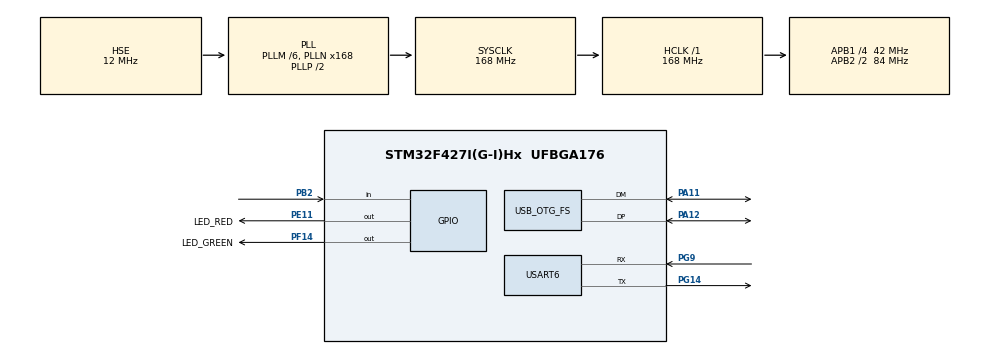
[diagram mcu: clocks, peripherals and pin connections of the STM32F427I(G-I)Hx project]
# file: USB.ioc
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Dma.Request0=USART6_RX
Dma.Request1=USART6_TX
Dma.USART6_RX.0.Direction=DMA_PERIPH_TO_MEMORY
Dma.USART6_RX.0.FIFOMode=DMA_FIFOMODE_DISABLE
Dma.USART6_RX.0.Instance=DMA2_Stream1
Dma.USART6_RX.0.MemDataAlignment=DMA_MDATAALIGN_BYTE
Dma.USART6_RX.0.MemInc=DMA_MINC_ENABLE
Dma.USART6_RX.0.Mode=DMA_NORMAL
Dma.USART6_RX.0.PeriphDataAlignment=DMA_PDATAALIGN_BYTE
Dma.USART6_RX.0.PeriphInc=DMA_PINC_DISABLE
Dma.USART6_RX.0.Priority=DMA_PRIORITY_LOW
Dma.USART6_TX.1.Direction=DMA_MEMORY_TO_PERIPH
Dma.USART6_TX.1.FIFOMode=DMA_FIFOMODE_DISABLE
Dma.USART6_TX.1.Instance=DMA2_Stream6
Dma.USART6_TX.1.MemDataAlignment=DMA_MDATAALIGN_BYTE
Dma.USART6_TX.1.MemInc=DMA_MINC_ENABLE
Dma.USART6_TX.1.Mode=DMA_NORMAL
Dma.USART6_TX.1.PeriphDataAlignment=DMA_PDATAALIGN_BYTE
Dma.USART6_TX.1.PeriphInc=DMA_PINC_DISABLE
Dma.USART6_TX.1.Priority=DMA_PRIORITY_LOW
Mcu.Family=STM32F4
Mcu.Name=STM32F427I(G-I)Hx
Mcu.Package=UFBGA176
NVIC.DMA2_Stream1_IRQn=true\:0\:0\:false\:false\:true\:false\:true\:true
NVIC.DMA2_Stream6_IRQn=true\:0\:0\:false\:false\:true\:false\:true\:true
NVIC.OTG_FS_IRQn=true\:0\:0\:false\:false\:true\:false\:true\:true
NVIC.PriorityGroup=NVIC_PRIORITYGROUP_4
NVIC.USART6_IRQn=true\:0\:0\:false\:false\:true\:true\:true\:true
PA11.Mode=Device_Only
PA11.Signal=USB_OTG_FS_DM
PA12.Mode=Device_Only
PA12.Signal=USB_OTG_FS_DP
PB2/BOOT1.Signal=GPIO_Input
PE11.GPIO_Label=LED_RED
PE11.Signal=GPIO_Output
PF14.GPIO_Label=LED_GREEN
PF14.Signal=GPIO_Output
PG14.Mode=Asynchronous
PG14.Signal=USART6_TX
PG9.Mode=Asynchronous
PG9.Signal=USART6_RX
PH0/OSC_IN.Mode=HSE-External-Oscillator
PH0/OSC_IN.Signal=RCC_OSC_IN
PH1/OSC_OUT.Mode=HSE-External-Oscillator
PH1/OSC_OUT.Signal=RCC_OSC_OUT
ProjectManager.HeapSize=0x1000
ProjectManager.StackSize=0x400
ProjectManager.TargetToolchain=Makefile
RCC.48MHZClocksFreq_Value=48000000
RCC.AHBFreq_Value=168000000
RCC.APB1CLKDivider=RCC_HCLK_DIV4
RCC.APB1Freq_Value=42000000
RCC.APB1TimFreq_Value=84000000
RCC.APB2CLKDivider=RCC_HCLK_DIV2
RCC.APB2Freq_Value=84000000
RCC.APB2TimFreq_Value=168000000
RCC.CortexFreq_Value=168000000
RCC.HCLKFreq_Value=168000000
RCC.HSE_VALUE=12000000
RCC.HSI_VALUE=16000000
RCC.LSE_VALUE=32768
RCC.PLLM=6
RCC.PLLN=168
RCC.PLLQ=7
RCC.SYSCLKFreq_VALUE=168000000
RCC.SYSCLKSource=RCC_SYSCLKSOURCE_PLLCLK
RCC.VCOOutputFreq_Value=336000000
USART6.VirtualMode=VM_ASYNC
USB_DEVICE.CLASS_NAME_FS=CDC
USB_DEVICE.VirtualMode-CDC_FS=Cdc
USB_DEVICE.VirtualModeFS=Cdc_FS
USB_OTG_FS.VirtualMode=Device_Only
VP_USB_DEVICE_VS_USB_DEVICE_CDC_FS.Mode=CDC_FS
board=USB

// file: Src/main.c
/**
  ******************************************************************************
  * @file           : main.c
  * @brief          : Main program body
  ******************************************************************************
  * This notice applies to any and all portions of this file
  * that are not between comment pairs USER CODE BEGIN and
  * USER CODE END. Other portions of this file, whether
  * inserted by the user or by software development tools
  * are owned by their respective copyright owners.
  *
  * Copyright (c) 2022 STMicroelectronics International N.V.
  * All rights reserved.
  *
  * Redistribution and use in source and binary forms, with or without
  * modification, are permitted, provided that the following conditions are met:
  *
  * 1. Redistribution of source code must retain the above copyright notice,
  *    this list of conditions and the following disclaimer.
  * 2. Redistributions in binary form must reproduce the above copyright notice,
  *    this list of conditions and the following disclaimer in the documentation
  *    and/or other materials provided with the distribution.
  * 3. Neither the name of STMicroelectronics nor the names of other
  *    contributors to this software may be used to endorse or promote products
  *    derived from this software without specific written permission.
  * 4. This software, including modifications and/or derivative works of this
  *    software, must execute solely and exclusively on microcontroller or
  *    microprocessor devices manufactured by or for STMicroelectronics.
  * 5. Redistribution and use of this software other than as permitted under
  *    this license is void and will automatically terminate your rights under
  *    this license.
  *
  * THIS SOFTWARE IS PROVIDED BY STMICROELECTRONICS AND CONTRIBUTORS "AS IS"
  * AND ANY EXPRESS, IMPLIED OR STATUTORY WARRANTIES, INCLUDING, BUT NOT
  * LIMITED TO, THE IMPLIED WARRANTIES OF MERCHANTABILITY, FITNESS FOR A
  * PARTICULAR PURPOSE AND NON-INFRINGEMENT OF THIRD PARTY INTELLECTUAL PROPERTY
  * RIGHTS ARE DISCLAIMED TO THE FULLEST EXTENT PERMITTED BY LAW. IN NO EVENT
  * SHALL STMICROELECTRONICS OR CONTRIBUTORS BE LIABLE FOR ANY DIRECT, INDIRECT,
  * INCIDENTAL, SPECIAL, EXEMPLARY, OR CONSEQUENTIAL DAMAGES (INCLUDING, BUT NOT
  * LIMITED TO, PROCUREMENT OF SUBSTITUTE GOODS OR SERVICES; LOSS OF USE, DATA,
  * OR PROFITS; OR BUSINESS INTERRUPTION) HOWEVER CAUSED AND ON ANY THEORY OF
  * LIABILITY, WHETHER IN CONTRACT, STRICT LIABILITY, OR TORT (INCLUDING
  * NEGLIGENCE OR OTHERWISE) ARISING IN ANY WAY OUT OF THE USE OF THIS SOFTWARE,
  * EVEN IF ADVISED OF THE POSSIBILITY OF SUCH DAMAGE.
  *
  ******************************************************************************
  */
#include "main.h"
#include "stm32f4xx_hal.h"
#include "dma.h"
#include "usart.h"
#include "usb_device.h"
#include "gpio.h"

/* USER CODE BEGIN PV */
/* Private variables ---------------------------------------------------------*/

uint8_t KeyStatus;
extern uint8_t UART_RxBuffer[2048];
/* USER CODE END PV */

void SystemClock_Config(void);

/* USER CODE BEGIN PFP */
/* Private function prototypes -----------------------------------------------*/

/* USER CODE END PFP */

int main(void)
{

  /* MCU Configuration----------------------------------------------------------*/

  /* Reset of all peripherals, Initializes the Flash interface and the Systick. */
  HAL_Init();

  /* Configure the system clock */
  SystemClock_Config();

  /* Initialize all configured peripherals */
  MX_GPIO_Init();
  MX_DMA_Init();
  MX_USB_DEVICE_Init();
  MX_USART6_UART_Init();
  /* USER CODE BEGIN 2 */
	led_off();
  /* Start UART Receive With IDLE Interrupt */
  HAL_UART_Receive_IT_IDLE(&huart6,UART_RxBuffer,2048);

  /* USER CODE END 2 */

  /* Infinite loop */
  while (1)
  {

  /* USER CODE BEGIN 3 */
	HAL_GPIO_TogglePin(LED_GREEN_GPIO_Port, LED_GREEN_Pin);
	HAL_Delay(500);
  }
  /* USER CODE END 3 */

}

void SystemClock_Config(void)
{

  RCC_OscInitTypeDef RCC_OscInitStruct;
  RCC_ClkInitTypeDef RCC_ClkInitStruct;

    /**Configure the main internal regulator output voltage
    */
  __HAL_RCC_PWR_CLK_ENABLE();

  __HAL_PWR_VOLTAGESCALING_CONFIG(PWR_REGULATOR_VOLTAGE_SCALE1);

    /**Initializes the CPU, AHB and APB busses clocks
    */
  RCC_OscInitStruct.OscillatorType = RCC_OSCILLATORTYPE_HSE;
  RCC_OscInitStruct.HSEState = RCC_HSE_ON;
  RCC_OscInitStruct.PLL.PLLState = RCC_PLL_ON;
  RCC_OscInitStruct.PLL.PLLSource = RCC_PLLSOURCE_HSE;
  RCC_OscInitStruct.PLL.PLLM = 6;
  RCC_OscInitStruct.PLL.PLLN = 168;
  RCC_OscInitStruct.PLL.PLLP = RCC_PLLP_DIV2;
  RCC_OscInitStruct.PLL.PLLQ = 7;
  if (HAL_RCC_OscConfig(&RCC_OscInitStruct) != HAL_OK)
  {
    _Error_Handler(__FILE__, __LINE__);
  }

    /**Initializes the CPU, AHB and APB busses clocks
    */
  RCC_ClkInitStruct.ClockType = RCC_CLOCKTYPE_HCLK|RCC_CLOCKTYPE_SYSCLK
                              |RCC_CLOCKTYPE_PCLK1|RCC_CLOCKTYPE_PCLK2;
  RCC_ClkInitStruct.SYSCLKSource = RCC_SYSCLKSOURCE_PLLCLK;
  RCC_ClkInitStruct.AHBCLKDivider = RCC_SYSCLK_DIV1;
  RCC_ClkInitStruct.APB1CLKDivider = RCC_HCLK_DIV4;
  RCC_ClkInitStruct.APB2CLKDivider = RCC_HCLK_DIV2;

  if (HAL_RCC_ClockConfig(&RCC_ClkInitStruct, FLASH_LATENCY_5) != HAL_OK)
  {
    _Error_Handler(__FILE__, __LINE__);
  }

    /**Configure the Systick interrupt time
    */
  HAL_SYSTICK_Config(HAL_RCC_GetHCLKFreq()/1000);

    /**Configure the Systick
    */
  HAL_SYSTICK_CLKSourceConfig(SYSTICK_CLKSOURCE_HCLK);

  /* SysTick_IRQn interrupt configuration */
  HAL_NVIC_SetPriority(SysTick_IRQn, 0, 0);
}

void _Error_Handler(char *file, int line)
{
  while(1)
  {
  }
}

/************************ (C) COPYRIGHT STMicroelectronics *****END OF FILE****/
